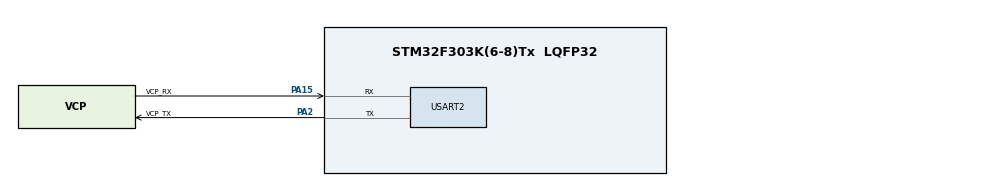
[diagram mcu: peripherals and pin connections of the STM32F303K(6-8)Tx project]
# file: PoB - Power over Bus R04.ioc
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Mcu.Family=STM32F3
Mcu.Name=STM32F303K(6-8)Tx
Mcu.Package=LQFP32
NVIC.PriorityGroup=NVIC_PRIORITYGROUP_4
PA13.GPIO_Label=SWDIO
PA13.Mode=Serial_Wire
PA13.Signal=SYS_JTMS-SWDIO
PA14.GPIO_Label=SWCLK
PA14.Mode=Serial_Wire
PA14.Signal=SYS_JTCK-SWCLK
PA15.GPIO_Label=VCP_RX
PA15.Mode=Asynchronous
PA15.Signal=USART2_RX
PA2.GPIO_Label=VCP_TX
PA2.Mode=Asynchronous
PA2.Signal=USART2_TX
PF0\ /\ OSC_IN.GPIO_Label=MCO
PF0\ /\ OSC_IN.Mode=HSE-External-Clock-Source
PF0\ /\ OSC_IN.Signal=RCC_OSC_IN
ProjectManager.HeapSize=0x200
ProjectManager.StackSize=0x400
ProjectManager.TargetToolchain=STM32CubeIDE
RCC.AHBFreq_Value=64000000
RCC.APB1CLKDivider=RCC_HCLK_DIV2
RCC.APB1Freq_Value=32000000
RCC.APB1TimFreq_Value=64000000
RCC.APB2Freq_Value=64000000
RCC.APB2TimFreq_Value=64000000
RCC.CortexFreq_Value=64000000
RCC.HCLKFreq_Value=64000000
RCC.HSE_VALUE=8000000
RCC.HSI_VALUE=8000000
RCC.PLLMUL=RCC_PLL_MUL16
RCC.SYSCLKFreq_VALUE=64000000
RCC.SYSCLKSourceVirtual=RCC_SYSCLKSOURCE_PLLCLK
USART2.VirtualMode-Asynchronous=VM_ASYNC
VP_CRC_VS_CRC.Mode=CRC_Activate
board=NUCLEO-F303K8

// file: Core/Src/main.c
/* USER CODE BEGIN Header */
/**
 ******************************************************************************
 * @file           : main.c
 * @brief          : Main program body
 ******************************************************************************
 * @attention
 *
 * Copyright (c) 2025 STMicroelectronics.
 * All rights reserved.
 *
 * This software is licensed under terms that can be found in the LICENSE file
 * in the root directory of this software component.
 * If no LICENSE file comes with this software, it is provided AS-IS.
 *
 ******************************************************************************
 */
/* USER CODE END Header */
#include "main.h"

/* USER CODE BEGIN Includes */

#include "protocol.h"
#include "uart.h"

/* USER CODE END Includes */

/* USER CODE BEGIN PD */

// Define the role of this device. Comment out the unused line.
#define MY_DEVICE_ROLE PROTOCOL_ROLE_MASTER
//#define MY_DEVICE_ROLE PROTOCOL_ROLE_SLAVE

/* USER CODE END PD */

/**
 * @brief Handle for the CRC peripheral. Required by the HAL library.
 */
CRC_HandleTypeDef hcrc;

/**
 * @brief Handle for the UART communication instance.
 * @note  This structure is initialized here and passed to the protocol and UART
 * layers. It contains all the necessary configuration for one UART interface.
 */
UART_Handle_t huart_comm;

void SystemClock_Config(void);
static void MX_GPIO_Init(void);
static void MX_USART2_UART_Init(void);
static void MX_CRC_Init(void);

int main(void)
{

  /* MCU Configuration--------------------------------------------------------*/

  /* Reset of all peripherals, Initializes the Flash interface and the Systick. */
  HAL_Init();

  /* Configure the system clock */
  SystemClock_Config();

  /* Initialize all configured peripherals */
  MX_GPIO_Init();
  MX_USART2_UART_Init();
  MX_CRC_Init();
  /* USER CODE BEGIN 2 */

	// --- Initialize the communication handle ---
	// This setup configures the application to use USART2.
	huart_comm.instance = USART2;
	huart_comm.dma_instance = DMA1;
	huart_comm.rx_dma_channel = LL_DMA_CHANNEL_6; // USART2_RX is on DMA1 Channel 6 for STM32F3
	huart_comm.tx_dma_channel = LL_DMA_CHANNEL_7; // USART2_TX is on DMA1 Channel 7 for STM32F3

	// --- Initialize the Protocol layer ---
	// This function will, in turn, initialize the underlying UART driver
	// with the handle provided and register the necessary callbacks.
	PROTOCOL_Init(&huart_comm, MY_DEVICE_ROLE);

  /* USER CODE END 2 */

  /* Infinite loop */
  /* USER CODE BEGIN WHILE */
	/* Infinite loop */
	while (1) {
		/*
		 * The main processing function of the protocol stack.
		 * This must be called continuously in the main loop. It runs the
		 * state machines for connection management, timeouts, and data handling.
		 */
		PROTOCOL_Process();

		/*
		 * FOR DEBUGGING:
		 * You can monitor the communication status by placing breakpoints here
		 * and watching these extern variables in your debugger's "Live Expressions" window:
		 *
		 * From protocol.h:
		 * - protocol_current_state:  The current state of the connection (e.g., CONNECTED_MASTER).
		 * - protocol_debug_stats:    Protocol-level event counters (pings, pongs, etc.).
		 * - latest_slave_stats:      The last received statistics from the slave.
		 *
		 * From uart.h (via the huart_comm handle):
		 * - huart_comm.stats:        Low-level UART statistics (CRC errors, overruns, etc.).
		 */
    /* USER CODE END WHILE */

	}
}

void SystemClock_Config(void)
{
  LL_FLASH_SetLatency(LL_FLASH_LATENCY_2);
  while(LL_FLASH_GetLatency()!= LL_FLASH_LATENCY_2)
  {
  }
  LL_RCC_HSI_Enable();

   /* Wait till HSI is ready */
  while(LL_RCC_HSI_IsReady() != 1)
  {

  }
  LL_RCC_HSI_SetCalibTrimming(16);
  LL_RCC_PLL_ConfigDomain_SYS(LL_RCC_PLLSOURCE_HSI_DIV_2, LL_RCC_PLL_MUL_16);
  LL_RCC_PLL_Enable();

   /* Wait till PLL is ready */
  while(LL_RCC_PLL_IsReady() != 1)
  {

  }
  LL_RCC_SetAHBPrescaler(LL_RCC_SYSCLK_DIV_1);
  LL_RCC_SetAPB1Prescaler(LL_RCC_APB1_DIV_2);
  LL_RCC_SetAPB2Prescaler(LL_RCC_APB2_DIV_1);
  LL_RCC_SetSysClkSource(LL_RCC_SYS_CLKSOURCE_PLL);

   /* Wait till System clock is ready */
  while(LL_RCC_GetSysClkSource() != LL_RCC_SYS_CLKSOURCE_STATUS_PLL)
  {

  }
  LL_SetSystemCoreClock(64000000);

   /* Update the time base */
  if (HAL_InitTick (TICK_INT_PRIORITY) != HAL_OK)
  {
    Error_Handler();
  }
}

static void MX_CRC_Init(void)
{

  hcrc.Instance = CRC;
  hcrc.Init.DefaultPolynomialUse = DEFAULT_POLYNOMIAL_ENABLE;
  hcrc.Init.DefaultInitValueUse = DEFAULT_INIT_VALUE_ENABLE;
  hcrc.Init.InputDataInversionMode = CRC_INPUTDATA_INVERSION_NONE;
  hcrc.Init.OutputDataInversionMode = CRC_OUTPUTDATA_INVERSION_DISABLE;
  hcrc.InputDataFormat = CRC_INPUTDATA_FORMAT_BYTES;
  if (HAL_CRC_Init(&hcrc) != HAL_OK)
  {
    Error_Handler();
  }

}

static void MX_USART2_UART_Init(void)
{

  LL_USART_InitTypeDef USART_InitStruct = {0};

  LL_GPIO_InitTypeDef GPIO_InitStruct = {0};

  /* Peripheral clock enable */
  LL_APB1_GRP1_EnableClock(LL_APB1_GRP1_PERIPH_USART2);

  LL_AHB1_GRP1_EnableClock(LL_AHB1_GRP1_PERIPH_GPIOA);
  /**USART2 GPIO Configuration
  PA2   ------> USART2_TX
  PA15   ------> USART2_RX
  */
  GPIO_InitStruct.Pin = VCP_TX_Pin|VCP_RX_Pin;
  GPIO_InitStruct.Mode = LL_GPIO_MODE_ALTERNATE;
  GPIO_InitStruct.Speed = LL_GPIO_SPEED_FREQ_HIGH;
  GPIO_InitStruct.OutputType = LL_GPIO_OUTPUT_PUSHPULL;
  GPIO_InitStruct.Pull = LL_GPIO_PULL_NO;
  GPIO_InitStruct.Alternate = LL_GPIO_AF_7;
  LL_GPIO_Init(GPIOA, &GPIO_InitStruct);

  USART_InitStruct.BaudRate = 38400;
  USART_InitStruct.DataWidth = LL_USART_DATAWIDTH_8B;
  USART_InitStruct.StopBits = LL_USART_STOPBITS_1;
  USART_InitStruct.Parity = LL_USART_PARITY_NONE;
  USART_InitStruct.TransferDirection = LL_USART_DIRECTION_TX_RX;
  USART_InitStruct.HardwareFlowControl = LL_USART_HWCONTROL_NONE;
  USART_InitStruct.OverSampling = LL_USART_OVERSAMPLING_16;
  LL_USART_Init(USART2, &USART_InitStruct);
  LL_USART_DisableIT_CTS(USART2);
  LL_USART_ConfigAsyncMode(USART2);
  LL_USART_Enable(USART2);

}

static void MX_GPIO_Init(void)
{

  /* GPIO Ports Clock Enable */
  LL_AHB1_GRP1_EnableClock(LL_AHB1_GRP1_PERIPH_GPIOF);
  LL_AHB1_GRP1_EnableClock(LL_AHB1_GRP1_PERIPH_GPIOA);

}

void Error_Handler(void)
{
	__disable_irq();
	while (1) {
	}
}
